AUTOSAR XML (schema 4-2-2)
package /STELLANTIS/EPT/ASWCs
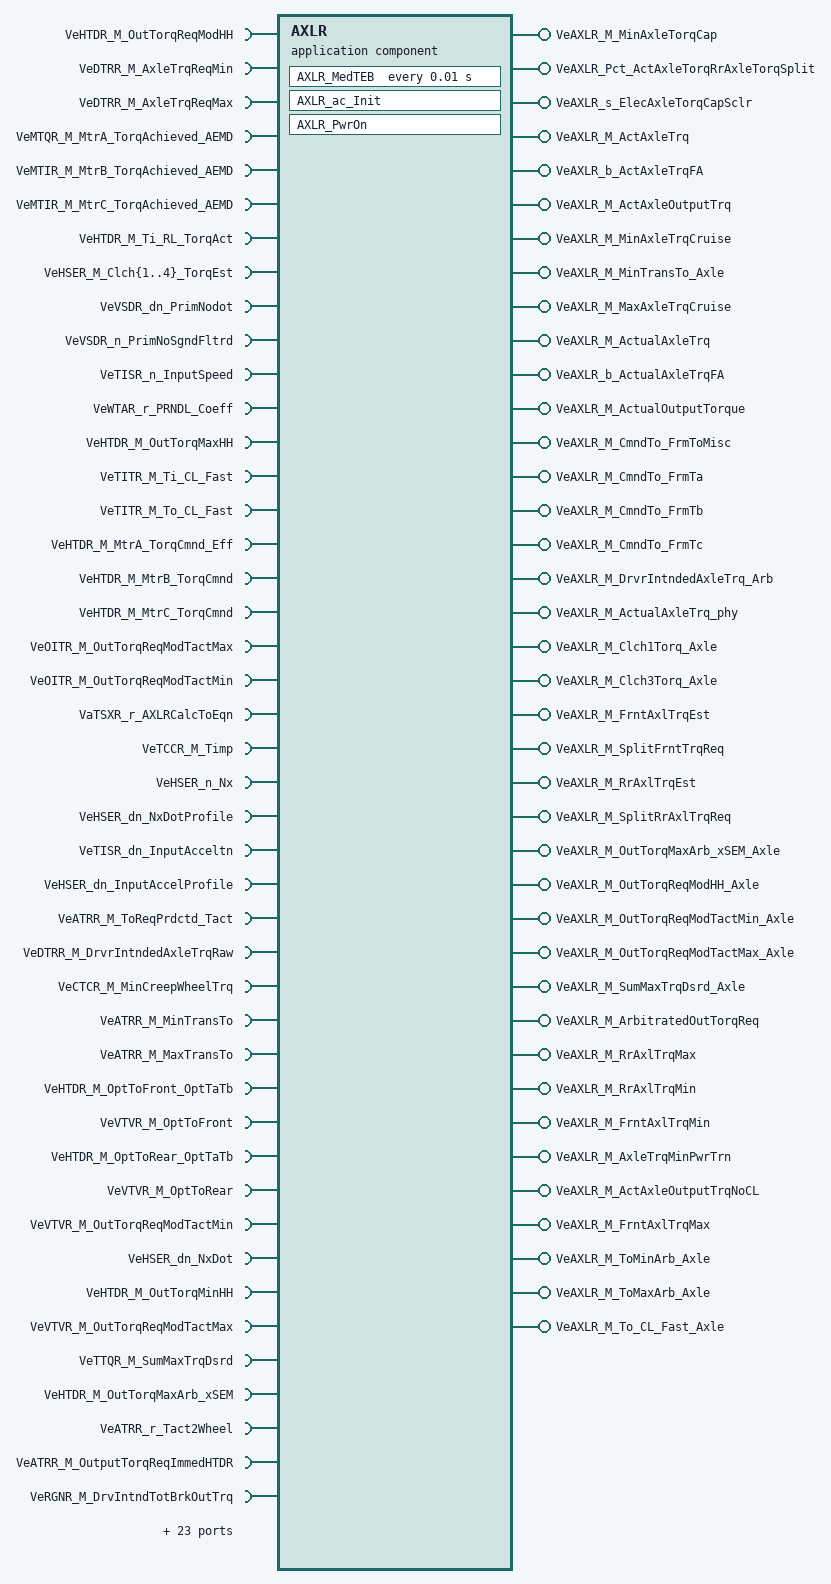
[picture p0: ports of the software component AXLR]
  application sw component type AXLR
    67 x require port:
      VeHTDR_M_OutTorqReqModHH: nonqueued-receiver-com-spec{data-element=Value, init-value=0}, required-interface=VeHTDR_M_OutTorqReqModHH
      VeDTRR_M_AxleTrqReqMin: nonqueued-receiver-com-spec{data-element=Value, init-value=0}, required-interface=VeDTRR_M_AxleTrqReqMin
      VeDTRR_M_AxleTrqReqMax: nonqueued-receiver-com-spec{data-element=Value, init-value=0}, required-interface=VeDTRR_M_AxleTrqReqMax
      VeMTQR_M_MtrA_TorqAchieved_AEMD: nonqueued-receiver-com-spec{data-element=Value, init-value=0}, required-interface=VeMTQR_M_MtrA_TorqAchieved_AEMD
      VeMTIR_M_MtrB_TorqAchieved_AEMD: nonqueued-receiver-com-spec{data-element=Value, init-value=0}, required-interface=VeMTIR_M_MtrB_TorqAchieved_AEMD
      VeMTIR_M_MtrC_TorqAchieved_AEMD: nonqueued-receiver-com-spec{data-element=Value, init-value=0}, required-interface=VeMTIR_M_MtrC_TorqAchieved_AEMD
      VeHTDR_M_Ti_RL_TorqAct: nonqueued-receiver-com-spec{data-element=Value, init-value=0}, required-interface=VeHTDR_M_Ti_RL_TorqAct
      VeHSER_M_Clch{1..4}_TorqEst: nonqueued-receiver-com-spec{data-element=Value, init-value=0}, required-interface=VeHSER_M_Clch{1..4}_TorqEst
      VeVSDR_dn_PrimNodot: nonqueued-receiver-com-spec{data-element=Value, init-value=0}, required-interface=VeVSDR_dn_PrimNodot
      VeVSDR_n_PrimNoSgndFltrd: nonqueued-receiver-com-spec{data-element=Value, init-value=0}, required-interface=VeVSDR_n_PrimNoSgndFltrd
      VeTISR_n_InputSpeed: nonqueued-receiver-com-spec{data-element=Value, init-value=0}, required-interface=VeTISR_n_InputSpeed
      VeWTAR_r_PRNDL_Coeff: nonqueued-receiver-com-spec{data-element=Value, init-value=0}, required-interface=VeWTAR_r_PRNDL_Coeff
      VeHTDR_M_OutTorqMaxHH: nonqueued-receiver-com-spec{data-element=Value, init-value=0}, required-interface=VeHTDR_M_OutTorqMaxHH
      VeTITR_M_Ti_CL_Fast: nonqueued-receiver-com-spec{data-element=Value, init-value=0}, required-interface=VeTITR_M_Ti_CL_Fast
      VeTITR_M_To_CL_Fast: nonqueued-receiver-com-spec{data-element=Value, init-value=0}, required-interface=VeTITR_M_To_CL_Fast
      VeHTDR_M_MtrA_TorqCmnd_Eff: nonqueued-receiver-com-spec{data-element=Value, init-value=0}, required-interface=VeHTDR_M_MtrA_TorqCmnd_Eff
      VeHTDR_M_MtrB_TorqCmnd: nonqueued-receiver-com-spec{data-element=Value, init-value=0}, required-interface=VeHTDR_M_MtrB_TorqCmnd
      VeHTDR_M_MtrC_TorqCmnd: nonqueued-receiver-com-spec{data-element=Value, init-value=0}, required-interface=VeHTDR_M_MtrC_TorqCmnd
      VeOITR_M_OutTorqReqModTactMax: nonqueued-receiver-com-spec{data-element=Value, init-value=0}, required-interface=VeOITR_M_OutTorqReqModTactMax
      VeOITR_M_OutTorqReqModTactMin: nonqueued-receiver-com-spec{data-element=Value, init-value=0}, required-interface=VeOITR_M_OutTorqReqModTactMin
      VaTSXR_r_AXLRCalcToEqn: nonqueued-receiver-com-spec{data-element=Value, init-value=19 x 0}, required-interface=VaTSXR_r_AXLRCalcToEqn
      VeTCCR_M_Timp: nonqueued-receiver-com-spec{data-element=Value, init-value=0}, required-interface=VeTCCR_M_Timp
      VeHSER_n_Nx: nonqueued-receiver-com-spec{data-element=Value, init-value=0}, required-interface=VeHSER_n_Nx
      VeHSER_dn_NxDotProfile: nonqueued-receiver-com-spec{data-element=Value, init-value=0}, required-interface=VeHSER_dn_NxDotProfile
      VeTISR_dn_InputAcceltn: nonqueued-receiver-com-spec{data-element=Value, init-value=0}, required-interface=VeTISR_dn_InputAcceltn
      VeHSER_dn_InputAccelProfile: nonqueued-receiver-com-spec{data-element=Value, init-value=0}, required-interface=VeHSER_dn_InputAccelProfile
      VeATRR_M_ToReqPrdctd_Tact: nonqueued-receiver-com-spec{data-element=Value, init-value=0}, required-interface=VeATRR_M_ToReqPrdctd_Tact
      VeDTRR_M_DrvrIntndedAxleTrqRaw: nonqueued-receiver-com-spec{data-element=Value, init-value=0}, required-interface=VeDTRR_M_DrvrIntndedAxleTrqRaw
      VeCTCR_M_MinCreepWheelTrq: nonqueued-receiver-com-spec{data-element=Value, init-value=0}, required-interface=VeCTCR_M_MinCreepWheelTrq
      VeATRR_M_MinTransTo: nonqueued-receiver-com-spec{data-element=Value, init-value=0}, required-interface=VeATRR_M_MinTransTo
      VeATRR_M_MaxTransTo: nonqueued-receiver-com-spec{data-element=Value, init-value=0}, required-interface=VeATRR_M_MaxTransTo
      VeHTDR_M_OptToFront_OptTaTb: variation-point={short-label=vpVeHTDR_M_OptToFront_OptTaTb, sw-syscond=1}, nonqueued-receiver-com-spec{data-element=Value, init-value=0}, required-interface=VeHTDR_M_OptToFront_OptTaTb
      VeVTVR_M_OptToFront: variation-point={short-label=vpVeVTVR_M_OptToFront, sw-syscond=1}, nonqueued-receiver-com-spec{data-element=Value, init-value=0}, required-interface=VeVTVR_M_OptToFront
      VeHTDR_M_OptToRear_OptTaTb: variation-point={short-label=vpVeHTDR_M_OptToRear_OptTaTb, sw-syscond=1}, nonqueued-receiver-com-spec{data-element=Value, init-value=0}, required-interface=VeHTDR_M_OptToRear_OptTaTb
      VeVTVR_M_OptToRear: variation-point={short-label=vpVeVTVR_M_OptToRear, sw-syscond=1}, nonqueued-receiver-com-spec{data-element=Value, init-value=0}, required-interface=VeVTVR_M_OptToRear
      VeVTVR_M_OutTorqReqModTactMin: nonqueued-receiver-com-spec{data-element=Value, init-value=0}, required-interface=VeVTVR_M_OutTorqReqModTactMin
      VeHSER_dn_NxDot: nonqueued-receiver-com-spec{data-element=Value, init-value=0}, required-interface=VeHSER_dn_NxDot
      VeHTDR_M_OutTorqMinHH: nonqueued-receiver-com-spec{data-element=Value, init-value=0}, required-interface=VeHTDR_M_OutTorqMinHH
      VeVTVR_M_OutTorqReqModTactMax: nonqueued-receiver-com-spec{data-element=Value, init-value=0}, required-interface=VeVTVR_M_OutTorqReqModTactMax
      VeTTQR_M_SumMaxTrqDsrd: nonqueued-receiver-com-spec{data-element=Value, init-value=0}, required-interface=VeTTQR_M_SumMaxTrqDsrd
      VeHTDR_M_OutTorqMaxArb_xSEM: nonqueued-receiver-com-spec{data-element=Value, init-value=0}, required-interface=VeHTDR_M_OutTorqMaxArb_xSEM
      VeATRR_r_Tact2Wheel: nonqueued-receiver-com-spec{data-element=Value, init-value=0}, required-interface=VeATRR_r_Tact2Wheel
      VeATRR_M_OutputTorqReqImmedHTDR: nonqueued-receiver-com-spec{data-element=Value, init-value=0}, required-interface=VeATRR_M_OutputTorqReqImmedHTDR
      VeRGNR_M_DrvIntndTotBrkOutTrq: nonqueued-receiver-com-spec{data-element=Value, init-value=0}, required-interface=VeRGNR_M_DrvIntndTotBrkOutTrq
      VeRGNR_M_RegenBrkOutTorqCap_Lin: nonqueued-receiver-com-spec{data-element=Value, init-value=0}, required-interface=VeRGNR_M_RegenBrkOutTorqCap_Lin
      VeATRR_M_OutTrqReqImmWithoutSEM: nonqueued-receiver-com-spec{data-element=Value, init-value=0}, required-interface=VeATRR_M_OutTrqReqImmWithoutSEM
      VeMSPR_n_MtrB_Spd: variation-point={short-label=vpVeMSPR_n_MtrB_Spd, sw-syscond=1}, nonqueued-receiver-com-spec{data-element=Value, init-value=0}, required-interface=VeMSPR_n_MtrB_Spd
      VeMSPR_n_MtrC_Spd: variation-point={short-label=vpVeMSPR_n_MtrC_Spd, sw-syscond=1}, nonqueued-receiver-com-spec{data-element=Value, init-value=0}, required-interface=VeMSPR_n_MtrC_Spd
      VeHTDR_M_ToFTgt_postRegen: variation-point={short-label=vpVeHTDR_M_ToFTgt_postRegen, sw-syscond=1}, nonqueued-receiver-com-spec{data-element=Value, init-value=0}, required-interface=VeHTDR_M_ToFTgt_postRegen
      VeHTDR_M_ToRTgt_postRegen: variation-point={short-label=vpVeHTDR_M_ToRTgt_postRegen, sw-syscond=1}, nonqueued-receiver-com-spec{data-element=Value, init-value=0}, required-interface=VeHTDR_M_ToRTgt_postRegen
      VeHTDR_M_Ta_Max_Allowed: variation-point={short-label=vpVeHTDR_M_Ta_Max_Allowed, sw-syscond=1}, nonqueued-receiver-com-spec{data-element=Value, init-value=0}, required-interface=VeHTDR_M_Ta_Max_Allowed
      VeHTDR_M_Ta_Min_Allowed: variation-point={short-label=vpVeHTDR_M_Ta_Min_Allowed, sw-syscond=1}, nonqueued-receiver-com-spec{data-element=Value, init-value=0}, required-interface=VeHTDR_M_Ta_Min_Allowed
      VeHTDR_M_Tb_Max_Allowed: variation-point={short-label=vpVeHTDR_M_Tb_Max_Allowed, sw-syscond=1}, nonqueued-receiver-com-spec{data-element=Value, init-value=0}, required-interface=VeHTDR_M_Tb_Max_Allowed
      VeHTDR_M_Tb_Min_Allowed: variation-point={short-label=vpVeHTDR_M_Tb_Min_Allowed, sw-syscond=1}, nonqueued-receiver-com-spec{data-element=Value, init-value=0}, required-interface=VeHTDR_M_Tb_Min_Allowed
      VeHTDR_M_Tc_Max_Allowed: variation-point={short-label=vpVeHTDR_M_Tc_Max_Allowed, sw-syscond=1}, nonqueued-receiver-com-spec{data-element=Value, init-value=0}, required-interface=VeHTDR_M_Tc_Max_Allowed
      VeHTDR_M_Tc_Min_Allowed: variation-point={short-label=vpVeHTDR_M_Tc_Min_Allowed, sw-syscond=1}, nonqueued-receiver-com-spec{data-element=Value, init-value=0}, required-interface=VeHTDR_M_Tc_Min_Allowed
      VeMSPR_n_MtrA_Spd: variation-point={short-label=vpVeMSPR_n_MtrA_Spd, sw-syscond=1}, nonqueued-receiver-com-spec{data-element=Value, init-value=0}, required-interface=VeMSPR_n_MtrA_Spd
      VaTSXR_r_AXLRCalcTofEqn: variation-point={short-label=vpVaTSXR_r_AXLRCalcTofEqn, sw-syscond=1}, nonqueued-receiver-com-spec{data-element=Value, init-value=19 x 0}, required-interface=VaTSXR_r_AXLRCalcTofEqn
      VaTSXR_r_AXLRCalcTorEqn: variation-point={short-label=vpVaTSXR_r_AXLRCalcTorEqn, sw-syscond=1}, nonqueued-receiver-com-spec{data-element=Value, init-value=19 x 0}, required-interface=VaTSXR_r_AXLRCalcTorEqn
      VeTTQR_M_SumTrqAct_SEM: nonqueued-receiver-com-spec{data-element=Value, init-value=0}, required-interface=VeTTQR_M_SumTrqAct_SEM
      VeTTQR_M_SumTrqStaticNoCL: nonqueued-receiver-com-spec{data-element=Value, init-value=0}, required-interface=VeTTQR_M_SumTrqStaticNoCL
      VeTTQR_M_SumTrqMinPwrTrn: nonqueued-receiver-com-spec{data-element=Value, init-value=0}, required-interface=VeTTQR_M_SumTrqMinPwrTrn
      VeTTIR_M_PumpTrqOnImpShaft: nonqueued-receiver-com-spec{data-element=Value, init-value=0}, required-interface=VeTTIR_M_PumpTrqOnImpShaft
      VeTCCR_r_TR: nonqueued-receiver-com-spec{data-element=Value, init-value=0}, required-interface=VeTCCR_r_TR
    39 x provide port, all with nonqueued-sender-com-spec{data-element=Value, init-value=0}:
      VeAXLR_M_MinAxleTorqCap: provided-interface=VeAXLR_M_MinAxleTorqCap
      VeAXLR_Pct_ActAxleTorqRrAxleTorqSplit: provided-interface=VeAXLR_Pct_ActAxleTorqRrAxleTorqSplit
      VeAXLR_s_ElecAxleTorqCapSclr: provided-interface=VeAXLR_s_ElecAxleTorqCapSclr
      VeAXLR_M_ActAxleTrq: provided-interface=VeAXLR_M_ActAxleTrq
      VeAXLR_b_ActAxleTrqFA: provided-interface=VeAXLR_b_ActAxleTrqFA
      VeAXLR_M_ActAxleOutputTrq: provided-interface=VeAXLR_M_ActAxleOutputTrq
      VeAXLR_M_MinAxleTrqCruise: provided-interface=VeAXLR_M_MinAxleTrqCruise
      VeAXLR_M_MinTransTo_Axle: provided-interface=VeAXLR_M_MinTransTo_Axle
      VeAXLR_M_MaxAxleTrqCruise: provided-interface=VeAXLR_M_MaxAxleTrqCruise
      VeAXLR_M_ActualAxleTrq: provided-interface=VeAXLR_M_ActualAxleTrq
      VeAXLR_b_ActualAxleTrqFA: provided-interface=VeAXLR_b_ActualAxleTrqFA
      VeAXLR_M_ActualOutputTorque: provided-interface=VeAXLR_M_ActualOutputTorque
      VeAXLR_M_CmndTo_FrmToMisc: provided-interface=VeAXLR_M_CmndTo_FrmToMisc
      VeAXLR_M_CmndTo_FrmTa: provided-interface=VeAXLR_M_CmndTo_FrmTa
      VeAXLR_M_CmndTo_FrmTb: provided-interface=VeAXLR_M_CmndTo_FrmTb
      VeAXLR_M_CmndTo_FrmTc: provided-interface=VeAXLR_M_CmndTo_FrmTc
      VeAXLR_M_DrvrIntndedAxleTrq_Arb: provided-interface=VeAXLR_M_DrvrIntndedAxleTrq_Arb
      VeAXLR_M_ActualAxleTrq_phy: provided-interface=VeAXLR_M_ActualAxleTrq_phy
      VeAXLR_M_Clch1Torq_Axle: provided-interface=VeAXLR_M_Clch1Torq_Axle
      VeAXLR_M_Clch3Torq_Axle: provided-interface=VeAXLR_M_Clch3Torq_Axle
      VeAXLR_M_FrntAxlTrqEst: provided-interface=VeAXLR_M_FrntAxlTrqEst
      VeAXLR_M_SplitFrntTrqReq: provided-interface=VeAXLR_M_SplitFrntTrqReq
      VeAXLR_M_RrAxlTrqEst: provided-interface=VeAXLR_M_RrAxlTrqEst
      VeAXLR_M_SplitRrAxlTrqReq: provided-interface=VeAXLR_M_SplitRrAxlTrqReq
      VeAXLR_M_OutTorqMaxArb_xSEM_Axle: provided-interface=VeAXLR_M_OutTorqMaxArb_xSEM_Axle
      VeAXLR_M_OutTorqReqModHH_Axle: provided-interface=VeAXLR_M_OutTorqReqModHH_Axle
      VeAXLR_M_OutTorqReqModTactMin_Axle: provided-interface=VeAXLR_M_OutTorqReqModTactMin_Axle
      VeAXLR_M_OutTorqReqModTactMax_Axle: provided-interface=VeAXLR_M_OutTorqReqModTactMax_Axle
      VeAXLR_M_SumMaxTrqDsrd_Axle: provided-interface=VeAXLR_M_SumMaxTrqDsrd_Axle
      VeAXLR_M_ArbitratedOutTorqReq: provided-interface=VeAXLR_M_ArbitratedOutTorqReq
      VeAXLR_M_RrAxlTrqMax: provided-interface=VeAXLR_M_RrAxlTrqMax
      VeAXLR_M_RrAxlTrqMin: provided-interface=VeAXLR_M_RrAxlTrqMin
      VeAXLR_M_FrntAxlTrqMin: provided-interface=VeAXLR_M_FrntAxlTrqMin
      VeAXLR_M_AxleTrqMinPwrTrn: provided-interface=VeAXLR_M_AxleTrqMinPwrTrn
      VeAXLR_M_ActAxleOutputTrqNoCL: provided-interface=VeAXLR_M_ActAxleOutputTrqNoCL
      VeAXLR_M_FrntAxlTrqMax: provided-interface=VeAXLR_M_FrntAxlTrqMax
      VeAXLR_M_ToMinArb_Axle: provided-interface=VeAXLR_M_ToMinArb_Axle
      VeAXLR_M_ToMaxArb_Axle: provided-interface=VeAXLR_M_ToMaxArb_Axle
      VeAXLR_M_To_CL_Fast_Axle: provided-interface=VeAXLR_M_To_CL_Fast_Axle
    require port HeTSXR_e_All_TactToDomain: parameter-require-com-spec{init-value=CeTSXR_e_AxleDomain, parameter=HeTSXR_e_All_TactToDomain}, required-interface=HeTSXR_e_All_TactToDomain
    require port HeATRR_b_BSGConvByps: parameter-require-com-spec{init-value=HeATRR_b_BSGConvByps_HeATRR_b_BSGConvByps:0, parameter=HeATRR_b_BSGConvByps}, required-interface=HeATRR_b_BSGConvByps
    require port HeATRR_b_RTC_Enbl: parameter-require-com-spec{init-value=HeATRR_b_RTC_Enbl_HeATRR_b_RTC_Enbl:0, parameter=HeATRR_b_RTC_Enbl}, required-interface=HeATRR_b_RTC_Enbl
    behavior IB_AXLR: data-type-mapping=msADTtoIDTMapping, handle-termination-and-restart=NO-SUPPORT
      timing event Event_MedTEB: start-on-event=AXLR_MedTEB, period=0.01
      init event Event_AXLR_ac_Init: start-on-event=AXLR_ac_Init
      init event Event_PwrOn: start-on-event=AXLR_PwrOn
      runnable AXLR_ac_Init
      runnable AXLR_PwrOn
        data-send-points:
          39 x access:
            OUT_VeAXLR_M_MinAxleTorqCap_Value: accessed-variable=VeAXLR_M_MinAxleTorqCap.Value
            OUT_VeAXLR_Pct_ActAxleTorqRrAxleTorqSplit_Value: accessed-variable=VeAXLR_Pct_ActAxleTorqRrAxleTorqSplit.Value
            OUT_VeAXLR_M_ActAxleOutputTrq_Value: accessed-variable=VeAXLR_M_ActAxleOutputTrq.Value
            OUT_VeAXLR_M_ActualAxleTrq_Value: accessed-variable=VeAXLR_M_ActualAxleTrq.Value
            OUT_VeAXLR_M_MaxAxleTrqCruise_Value: accessed-variable=VeAXLR_M_MaxAxleTrqCruise.Value
            OUT_VeAXLR_M_MinAxleTrqCruise_Value: accessed-variable=VeAXLR_M_MinAxleTrqCruise.Value
            OUT_VeAXLR_M_ActualOutputTorque_Value: accessed-variable=VeAXLR_M_ActualOutputTorque.Value
            OUT_VeAXLR_M_CmndTo_FrmTa_Value: accessed-variable=VeAXLR_M_CmndTo_FrmTa.Value
            OUT_VeAXLR_M_CmndTo_FrmTb_Value: accessed-variable=VeAXLR_M_CmndTo_FrmTb.Value
            OUT_VeAXLR_M_CmndTo_FrmToMisc_Value: accessed-variable=VeAXLR_M_CmndTo_FrmToMisc.Value
            OUT_VeAXLR_M_DrvrIntndedAxleTrq_Arb_Value: accessed-variable=VeAXLR_M_DrvrIntndedAxleTrq_Arb.Value
            OUT_VeAXLR_M_ActualAxleTrq_phy_Value: accessed-variable=VeAXLR_M_ActualAxleTrq_phy.Value
            OUT_VeAXLR_M_ArbitratedOutTorqReq_Value: accessed-variable=VeAXLR_M_ArbitratedOutTorqReq.Value
            OUT_VeAXLR_M_Clch3Torq_Axle_Value: accessed-variable=VeAXLR_M_Clch3Torq_Axle.Value
            OUT_VeAXLR_M_CmndTo_FrmTc_Value: accessed-variable=VeAXLR_M_CmndTo_FrmTc.Value
            OUT_VeAXLR_M_OutTorqMaxArb_xSEM_Axle_Value: accessed-variable=VeAXLR_M_OutTorqMaxArb_xSEM_Axle.Value
            OUT_VeAXLR_s_ElecAxleTorqCapSclr_Value: accessed-variable=VeAXLR_s_ElecAxleTorqCapSclr.Value
            OUT_VeAXLR_M_OutTorqReqModHH_Axle_Value: accessed-variable=VeAXLR_M_OutTorqReqModHH_Axle.Value
            OUT_VeAXLR_M_OutTorqReqModTactMin_Axle_Value: accessed-variable=VeAXLR_M_OutTorqReqModTactMin_Axle.Value
            OUT_VeAXLR_M_OutTorqReqModTactMax_Axle_Value: accessed-variable=VeAXLR_M_OutTorqReqModTactMax_Axle.Value
            OUT_VeAXLR_M_SumMaxTrqDsrd_Axle_Value: accessed-variable=VeAXLR_M_SumMaxTrqDsrd_Axle.Value
            OUT_VeAXLR_M_MinTransTo_Axle_Value: accessed-variable=VeAXLR_M_MinTransTo_Axle.Value
            OUT_VeAXLR_M_ActAxleTrq_Value: accessed-variable=VeAXLR_M_ActAxleTrq.Value
            OUT_VeAXLR_b_ActAxleTrqFA_Value: accessed-variable=VeAXLR_b_ActAxleTrqFA.Value
            OUT_VeAXLR_b_ActualAxleTrqFA_Value: accessed-variable=VeAXLR_b_ActualAxleTrqFA.Value
            OUT_VeAXLR_M_Clch1Torq_Axle_Value: accessed-variable=VeAXLR_M_Clch1Torq_Axle.Value
            OUT_VeAXLR_M_FrntAxlTrqEst_Value: accessed-variable=VeAXLR_M_FrntAxlTrqEst.Value
            OUT_VeAXLR_M_SplitFrntTrqReq_Value: accessed-variable=VeAXLR_M_SplitFrntTrqReq.Value
            OUT_VeAXLR_M_RrAxlTrqEst_Value: accessed-variable=VeAXLR_M_RrAxlTrqEst.Value
            OUT_VeAXLR_M_SplitRrAxlTrqReq_Value: accessed-variable=VeAXLR_M_SplitRrAxlTrqReq.Value
            OUT_VeAXLR_M_ToMinArb_Axle_Value: accessed-variable=VeAXLR_M_ToMinArb_Axle.Value
            OUT_VeAXLR_M_ToMaxArb_Axle_Value: accessed-variable=VeAXLR_M_ToMaxArb_Axle.Value
            OUT_VeAXLR_M_FrntAxlTrqMax_Value: accessed-variable=VeAXLR_M_FrntAxlTrqMax.Value
            OUT_VeAXLR_M_FrntAxlTrqMin_Value: accessed-variable=VeAXLR_M_FrntAxlTrqMin.Value
            OUT_VeAXLR_M_RrAxlTrqMax_Value: accessed-variable=VeAXLR_M_RrAxlTrqMax.Value
            OUT_VeAXLR_M_RrAxlTrqMin_Value: accessed-variable=VeAXLR_M_RrAxlTrqMin.Value
            OUT_VeAXLR_M_AxleTrqMinPwrTrn_Value: accessed-variable=VeAXLR_M_AxleTrqMinPwrTrn.Value
            OUT_VeAXLR_M_ActAxleOutputTrqNoCL_Value: accessed-variable=VeAXLR_M_ActAxleOutputTrqNoCL.Value
            OUT_VeAXLR_M_To_CL_Fast_Axle_Value: accessed-variable=VeAXLR_M_To_CL_Fast_Axle.Value
      runnable AXLR_MedTEB
        data-receive-point-by-arguments:
          67 x access:
            IN_VaTSXR_r_AXLRCalcToEqn_Value: accessed-variable=VaTSXR_r_AXLRCalcToEqn.Value
            IN_VaTSXR_r_AXLRCalcTofEqn_Value: accessed-variable=VaTSXR_r_AXLRCalcTofEqn.Value, variation-point={short-label=vpIN_VaTSXR_r_AXLRCalcTofEqn_Value, sw-syscond=1}
            IN_VaTSXR_r_AXLRCalcTorEqn_Value: accessed-variable=VaTSXR_r_AXLRCalcTorEqn.Value, variation-point={short-label=vpIN_VaTSXR_r_AXLRCalcTorEqn_Value, sw-syscond=1}
            IN_VeATRR_M_MaxTransTo_Value: accessed-variable=VeATRR_M_MaxTransTo.Value
            IN_VeATRR_M_MinTransTo_Value: accessed-variable=VeATRR_M_MinTransTo.Value
            IN_VeATRR_M_OutTrqReqImmWithoutSEM_Value: accessed-variable=VeATRR_M_OutTrqReqImmWithoutSEM.Value
            IN_VeATRR_M_OutputTorqReqImmedHTDR_Value: accessed-variable=VeATRR_M_OutputTorqReqImmedHTDR.Value
            IN_VeATRR_M_ToReqPrdctd_Tact_Value: accessed-variable=VeATRR_M_ToReqPrdctd_Tact.Value
            IN_VeATRR_r_Tact2Wheel_Value: accessed-variable=VeATRR_r_Tact2Wheel.Value
            IN_VeCTCR_M_MinCreepWheelTrq_Value: accessed-variable=VeCTCR_M_MinCreepWheelTrq.Value
            IN_VeDTRR_M_AxleTrqReqMax_Value: accessed-variable=VeDTRR_M_AxleTrqReqMax.Value
            IN_VeDTRR_M_AxleTrqReqMin_Value: accessed-variable=VeDTRR_M_AxleTrqReqMin.Value
            IN_VeDTRR_M_DrvrIntndedAxleTrqRaw_Value: accessed-variable=VeDTRR_M_DrvrIntndedAxleTrqRaw.Value
            IN_VeHSER_M_Clch{1..4}_TorqEst_Value: accessed-variable=VeHSER_M_Clch{1..4}_TorqEst.Value
            IN_VeHSER_dn_InputAccelProfile_Value: accessed-variable=VeHSER_dn_InputAccelProfile.Value
            IN_VeHSER_dn_NxDot_Value: accessed-variable=VeHSER_dn_NxDot.Value
            IN_VeHSER_dn_NxDotProfile_Value: accessed-variable=VeHSER_dn_NxDotProfile.Value
            IN_VeHSER_n_Nx_Value: accessed-variable=VeHSER_n_Nx.Value
            IN_VeHTDR_M_MtrA_TorqCmnd_Eff_Value: accessed-variable=VeHTDR_M_MtrA_TorqCmnd_Eff.Value
            IN_VeHTDR_M_MtrB_TorqCmnd_Value: accessed-variable=VeHTDR_M_MtrB_TorqCmnd.Value
            IN_VeHTDR_M_MtrC_TorqCmnd_Value: accessed-variable=VeHTDR_M_MtrC_TorqCmnd.Value
            IN_VeHTDR_M_OptToFront_OptTaTb_Value: accessed-variable=VeHTDR_M_OptToFront_OptTaTb.Value, variation-point={short-label=vpIN_VeHTDR_M_OptToFront_OptTaTb_Value, sw-syscond=1}
            IN_VeHTDR_M_OptToRear_OptTaTb_Value: accessed-variable=VeHTDR_M_OptToRear_OptTaTb.Value, variation-point={short-label=vpIN_VeHTDR_M_OptToRear_OptTaTb_Value, sw-syscond=1}
            IN_VeHTDR_M_OutTorqMaxArb_xSEM_Value: accessed-variable=VeHTDR_M_OutTorqMaxArb_xSEM.Value
            IN_VeHTDR_M_OutTorqMaxHH_Value: accessed-variable=VeHTDR_M_OutTorqMaxHH.Value
            IN_VeHTDR_M_OutTorqMinHH_Value: accessed-variable=VeHTDR_M_OutTorqMinHH.Value
            IN_VeHTDR_M_OutTorqReqModHH_Value: accessed-variable=VeHTDR_M_OutTorqReqModHH.Value
            IN_VeHTDR_M_Ta_Max_Allowed_Value: accessed-variable=VeHTDR_M_Ta_Max_Allowed.Value, variation-point={short-label=vpIN_VeHTDR_M_Ta_Max_Allowed_Value, sw-syscond=1}
            IN_VeHTDR_M_Ta_Min_Allowed_Value: accessed-variable=VeHTDR_M_Ta_Min_Allowed.Value, variation-point={short-label=vpIN_VeHTDR_M_Ta_Min_Allowed_Value, sw-syscond=1}
            IN_VeHTDR_M_Tb_Max_Allowed_Value: accessed-variable=VeHTDR_M_Tb_Max_Allowed.Value, variation-point={short-label=vpIN_VeHTDR_M_Tb_Max_Allowed_Value, sw-syscond=1}
            IN_VeHTDR_M_Tb_Min_Allowed_Value: accessed-variable=VeHTDR_M_Tb_Min_Allowed.Value, variation-point={short-label=vpIN_VeHTDR_M_Tb_Min_Allowed_Value, sw-syscond=1}
            IN_VeHTDR_M_Tc_Max_Allowed_Value: accessed-variable=VeHTDR_M_Tc_Max_Allowed.Value, variation-point={short-label=vpIN_VeHTDR_M_Tc_Max_Allowed_Value, sw-syscond=1}
            IN_VeHTDR_M_Tc_Min_Allowed_Value: accessed-variable=VeHTDR_M_Tc_Min_Allowed.Value, variation-point={short-label=vpIN_VeHTDR_M_Tc_Min_Allowed_Value, sw-syscond=1}
            IN_VeHTDR_M_Ti_RL_TorqAct_Value: accessed-variable=VeHTDR_M_Ti_RL_TorqAct.Value
            IN_VeHTDR_M_ToFTgt_postRegen_Value: accessed-variable=VeHTDR_M_ToFTgt_postRegen.Value, variation-point={short-label=vpIN_VeHTDR_M_ToFTgt_postRegen_Value, sw-syscond=1}
            IN_VeHTDR_M_ToRTgt_postRegen_Value: accessed-variable=VeHTDR_M_ToRTgt_postRegen.Value, variation-point={short-label=vpIN_VeHTDR_M_ToRTgt_postRegen_Value, sw-syscond=1}
            IN_VeMSPR_n_MtrA_Spd_Value: accessed-variable=VeMSPR_n_MtrA_Spd.Value, variation-point={short-label=vpIN_VeMSPR_n_MtrA_Spd_Value, sw-syscond=1}
            IN_VeMSPR_n_MtrB_Spd_Value: accessed-variable=VeMSPR_n_MtrB_Spd.Value, variation-point={short-label=vpIN_VeMSPR_n_MtrB_Spd_Value, sw-syscond=1}
            IN_VeMSPR_n_MtrC_Spd_Value: accessed-variable=VeMSPR_n_MtrC_Spd.Value, variation-point={short-label=vpIN_VeMSPR_n_MtrC_Spd_Value, sw-syscond=1}
            IN_VeMTIR_M_MtrB_TorqAchieved_AEMD_Value: accessed-variable=VeMTIR_M_MtrB_TorqAchieved_AEMD.Value
            IN_VeMTIR_M_MtrC_TorqAchieved_AEMD_Value: accessed-variable=VeMTIR_M_MtrC_TorqAchieved_AEMD.Value
            IN_VeMTQR_M_MtrA_TorqAchieved_AEMD_Value: accessed-variable=VeMTQR_M_MtrA_TorqAchieved_AEMD.Value
            IN_VeOITR_M_OutTorqReqModTactMax_Value: accessed-variable=VeOITR_M_OutTorqReqModTactMax.Value
            IN_VeOITR_M_OutTorqReqModTactMin_Value: accessed-variable=VeOITR_M_OutTorqReqModTactMin.Value
            IN_VeRGNR_M_DrvIntndTotBrkOutTrq_Value: accessed-variable=VeRGNR_M_DrvIntndTotBrkOutTrq.Value
            IN_VeRGNR_M_RegenBrkOutTorqCap_Lin_Value: accessed-variable=VeRGNR_M_RegenBrkOutTorqCap_Lin.Value
            IN_VeTCCR_M_Timp_Value: accessed-variable=VeTCCR_M_Timp.Value
            IN_VeTCCR_r_TR_Value: accessed-variable=VeTCCR_r_TR.Value
            IN_VeTISR_dn_InputAcceltn_Value: accessed-variable=VeTISR_dn_InputAcceltn.Value
            IN_VeTISR_n_InputSpeed_Value: accessed-variable=VeTISR_n_InputSpeed.Value
            IN_VeTITR_M_Ti_CL_Fast_Value: accessed-variable=VeTITR_M_Ti_CL_Fast.Value
            IN_VeTITR_M_To_CL_Fast_Value: accessed-variable=VeTITR_M_To_CL_Fast.Value
            IN_VeTTIR_M_PumpTrqOnImpShaft_Value: accessed-variable=VeTTIR_M_PumpTrqOnImpShaft.Value
            IN_VeTTQR_M_SumMaxTrqDsrd_Value: accessed-variable=VeTTQR_M_SumMaxTrqDsrd.Value
            IN_VeTTQR_M_SumTrqAct_SEM_Value: accessed-variable=VeTTQR_M_SumTrqAct_SEM.Value
            IN_VeTTQR_M_SumTrqMinPwrTrn_Value: accessed-variable=VeTTQR_M_SumTrqMinPwrTrn.Value
            IN_VeTTQR_M_SumTrqStaticNoCL_Value: accessed-variable=VeTTQR_M_SumTrqStaticNoCL.Value
            IN_VeVSDR_dn_PrimNodot_Value: accessed-variable=VeVSDR_dn_PrimNodot.Value
            IN_VeVSDR_n_PrimNoSgndFltrd_Value: accessed-variable=VeVSDR_n_PrimNoSgndFltrd.Value
            IN_VeVTVR_M_OptToFront_Value: accessed-variable=VeVTVR_M_OptToFront.Value, variation-point={short-label=vpIN_VeVTVR_M_OptToFront_Value, sw-syscond=1}
            IN_VeVTVR_M_OptToRear_Value: accessed-variable=VeVTVR_M_OptToRear.Value, variation-point={short-label=vpIN_VeVTVR_M_OptToRear_Value, sw-syscond=1}
            IN_VeVTVR_M_OutTorqReqModTactMax_Value: accessed-variable=VeVTVR_M_OutTorqReqModTactMax.Value
            IN_VeVTVR_M_OutTorqReqModTactMin_Value: accessed-variable=VeVTVR_M_OutTorqReqModTactMin.Value
            IN_VeWTAR_r_PRNDL_Coeff_Value: accessed-variable=VeWTAR_r_PRNDL_Coeff.Value
        data-send-points:
          39 x access:
            OUT_VeAXLR_M_MinAxleTorqCap_Value: accessed-variable=VeAXLR_M_MinAxleTorqCap.Value
            OUT_VeAXLR_Pct_ActAxleTorqRrAxleTorqSplit_Value: accessed-variable=VeAXLR_Pct_ActAxleTorqRrAxleTorqSplit.Value
            OUT_VeAXLR_M_ActAxleOutputTrq_Value: accessed-variable=VeAXLR_M_ActAxleOutputTrq.Value
            OUT_VeAXLR_M_ActualAxleTrq_Value: accessed-variable=VeAXLR_M_ActualAxleTrq.Value
            OUT_VeAXLR_M_MaxAxleTrqCruise_Value: accessed-variable=VeAXLR_M_MaxAxleTrqCruise.Value
            OUT_VeAXLR_M_MinAxleTrqCruise_Value: accessed-variable=VeAXLR_M_MinAxleTrqCruise.Value
            OUT_VeAXLR_M_ActualOutputTorque_Value: accessed-variable=VeAXLR_M_ActualOutputTorque.Value
            OUT_VeAXLR_M_CmndTo_FrmTa_Value: accessed-variable=VeAXLR_M_CmndTo_FrmTa.Value
            OUT_VeAXLR_M_CmndTo_FrmTb_Value: accessed-variable=VeAXLR_M_CmndTo_FrmTb.Value
            OUT_VeAXLR_M_CmndTo_FrmToMisc_Value: accessed-variable=VeAXLR_M_CmndTo_FrmToMisc.Value
            OUT_VeAXLR_M_DrvrIntndedAxleTrq_Arb_Value: accessed-variable=VeAXLR_M_DrvrIntndedAxleTrq_Arb.Value
            OUT_VeAXLR_M_ActualAxleTrq_phy_Value: accessed-variable=VeAXLR_M_ActualAxleTrq_phy.Value
            OUT_VeAXLR_M_ArbitratedOutTorqReq_Value: accessed-variable=VeAXLR_M_ArbitratedOutTorqReq.Value
            OUT_VeAXLR_M_Clch3Torq_Axle_Value: accessed-variable=VeAXLR_M_Clch3Torq_Axle.Value
            OUT_VeAXLR_M_CmndTo_FrmTc_Value: accessed-variable=VeAXLR_M_CmndTo_FrmTc.Value
            OUT_VeAXLR_M_OutTorqMaxArb_xSEM_Axle_Value: accessed-variable=VeAXLR_M_OutTorqMaxArb_xSEM_Axle.Value
            OUT_VeAXLR_s_ElecAxleTorqCapSclr_Value: accessed-variable=VeAXLR_s_ElecAxleTorqCapSclr.Value
            OUT_VeAXLR_M_OutTorqReqModHH_Axle_Value: accessed-variable=VeAXLR_M_OutTorqReqModHH_Axle.Value
            OUT_VeAXLR_M_OutTorqReqModTactMin_Axle_Value: accessed-variable=VeAXLR_M_OutTorqReqModTactMin_Axle.Value
            OUT_VeAXLR_M_OutTorqReqModTactMax_Axle_Value: accessed-variable=VeAXLR_M_OutTorqReqModTactMax_Axle.Value
            OUT_VeAXLR_M_SumMaxTrqDsrd_Axle_Value: accessed-variable=VeAXLR_M_SumMaxTrqDsrd_Axle.Value
            OUT_VeAXLR_M_MinTransTo_Axle_Value: accessed-variable=VeAXLR_M_MinTransTo_Axle.Value
            OUT_VeAXLR_M_ActAxleTrq_Value: accessed-variable=VeAXLR_M_ActAxleTrq.Value
            OUT_VeAXLR_b_ActAxleTrqFA_Value: accessed-variable=VeAXLR_b_ActAxleTrqFA.Value
            OUT_VeAXLR_b_ActualAxleTrqFA_Value: accessed-variable=VeAXLR_b_ActualAxleTrqFA.Value
            OUT_VeAXLR_M_Clch1Torq_Axle_Value: accessed-variable=VeAXLR_M_Clch1Torq_Axle.Value
            OUT_VeAXLR_M_FrntAxlTrqEst_Value: accessed-variable=VeAXLR_M_FrntAxlTrqEst.Value
            OUT_VeAXLR_M_SplitFrntTrqReq_Value: accessed-variable=VeAXLR_M_SplitFrntTrqReq.Value
            OUT_VeAXLR_M_RrAxlTrqEst_Value: accessed-variable=VeAXLR_M_RrAxlTrqEst.Value
            OUT_VeAXLR_M_SplitRrAxlTrqReq_Value: accessed-variable=VeAXLR_M_SplitRrAxlTrqReq.Value
            OUT_VeAXLR_M_FrntAxlTrqMax_Value: accessed-variable=VeAXLR_M_FrntAxlTrqMax.Value
            OUT_VeAXLR_M_FrntAxlTrqMin_Value: accessed-variable=VeAXLR_M_FrntAxlTrqMin.Value
            OUT_VeAXLR_M_RrAxlTrqMax_Value: accessed-variable=VeAXLR_M_RrAxlTrqMax.Value
            OUT_VeAXLR_M_RrAxlTrqMin_Value: accessed-variable=VeAXLR_M_RrAxlTrqMin.Value
            OUT_VeAXLR_M_ActAxleOutputTrqNoCL_Value: accessed-variable=VeAXLR_M_ActAxleOutputTrqNoCL.Value
            OUT_VeAXLR_M_AxleTrqMinPwrTrn_Value: accessed-variable=VeAXLR_M_AxleTrqMinPwrTrn.Value
            OUT_VeAXLR_M_ToMinArb_Axle_Value: accessed-variable=VeAXLR_M_ToMinArb_Axle.Value
            OUT_VeAXLR_M_ToMaxArb_Axle_Value: accessed-variable=VeAXLR_M_ToMaxArb_Axle.Value
            OUT_VeAXLR_M_To_CL_Fast_Axle_Value: accessed-variable=VeAXLR_M_To_CL_Fast_Axle.Value
        parameter access CALPRM_HeATRR_b_BSGConvByps_HeATRR_b_BSGConvByps: accessed-parameter=HeATRR_b_BSGConvByps.HeATRR_b_BSGConvByps
        parameter access CALPRM_HeATRR_b_RTC_Enbl_HeATRR_b_RTC_Enbl: accessed-parameter=HeATRR_b_RTC_Enbl.HeATRR_b_RTC_Enbl
        parameter access CALPRM_HeTSXR_e_All_TactToDomain_HeTSXR_e_All_TactToDomain: accessed-parameter=HeTSXR_e_All_TactToDomain.HeTSXR_e_All_TactToDomain
      variation point proxy Variant_AXLR_CstmCoeffActualAxleTrq_phy: category=CONDITION, condition-access=0
      variation point proxy Variant_AXLR_Dual_Axis: category=CONDITION, condition-access=1
      variation point proxy Variant_AXLR_RTC_On: category=CONDITION, condition-access=0
